AUTOSAR XML (schema 4-0-3)
standard types defined: UInt32, UInt8
package /AUTOSAR_Platform/DataConstrs
  range DC_UInt8: raw 0..255
package /PATAC/MSM/ComponentTypes
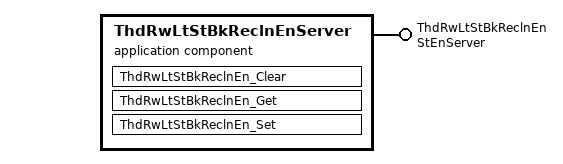
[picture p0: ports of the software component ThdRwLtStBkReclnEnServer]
  application sw component type ThdRwLtStBkReclnEnServer
    provide port ThdRwLtStBkReclnEn: provided-com-specs=[{operation=Clear, queue-length=1}, {operation=Get, queue-length=1}, {operation=Set, queue-length=1}], provided-interface=StEnServer
    behavior ThdRwLtStBkReclnEnServer_InternalBehavior
      operation invoked event OIT_ThdRwLtStBkReclnEn_Clear_ThdRwLtStBkReclnEn_Clear: start-on-event=ThdRwLtStBkReclnEn_Clear, operation=ThdRwLtStBkReclnEn.Clear
      operation invoked event OIT_ThdRwLtStBkReclnEn_Get_ThdRwLtStBkReclnEn_Get: start-on-event=ThdRwLtStBkReclnEn_Get, operation=ThdRwLtStBkReclnEn.Get
      operation invoked event OIT_ThdRwLtStBkReclnEn_Set_ThdRwLtStBkReclnEn_Set: start-on-event=ThdRwLtStBkReclnEn_Set, operation=ThdRwLtStBkReclnEn.Set
      runnable ThdRwLtStBkReclnEn_Clear
      runnable ThdRwLtStBkReclnEn_Get
      runnable ThdRwLtStBkReclnEn_Set
  swc implementation ThdRwLtStBkReclnEnServer_Implementation: behavior=ThdRwLtStBkReclnEnServer_InternalBehavior
    code-descriptors:
      code Default: artifact-descriptors=autosar-engineering-object={short-label=Default, category=SWSRC}
package /PATAC/MSM/ModeAdjust/PortInterface
  client server interface StEnServer
    operation Clear
      arg data: type=UInt8, direction=IN, server-argument-impl-policy=USE-ARGUMENT-TYPE
    operation Get
      arg data: type=UInt32, direction=OUT, server-argument-impl-policy=USE-ARGUMENT-TYPE
    operation Set
      arg data: type=UInt8, direction=IN, server-argument-impl-policy=USE-ARGUMENT-TYPE
